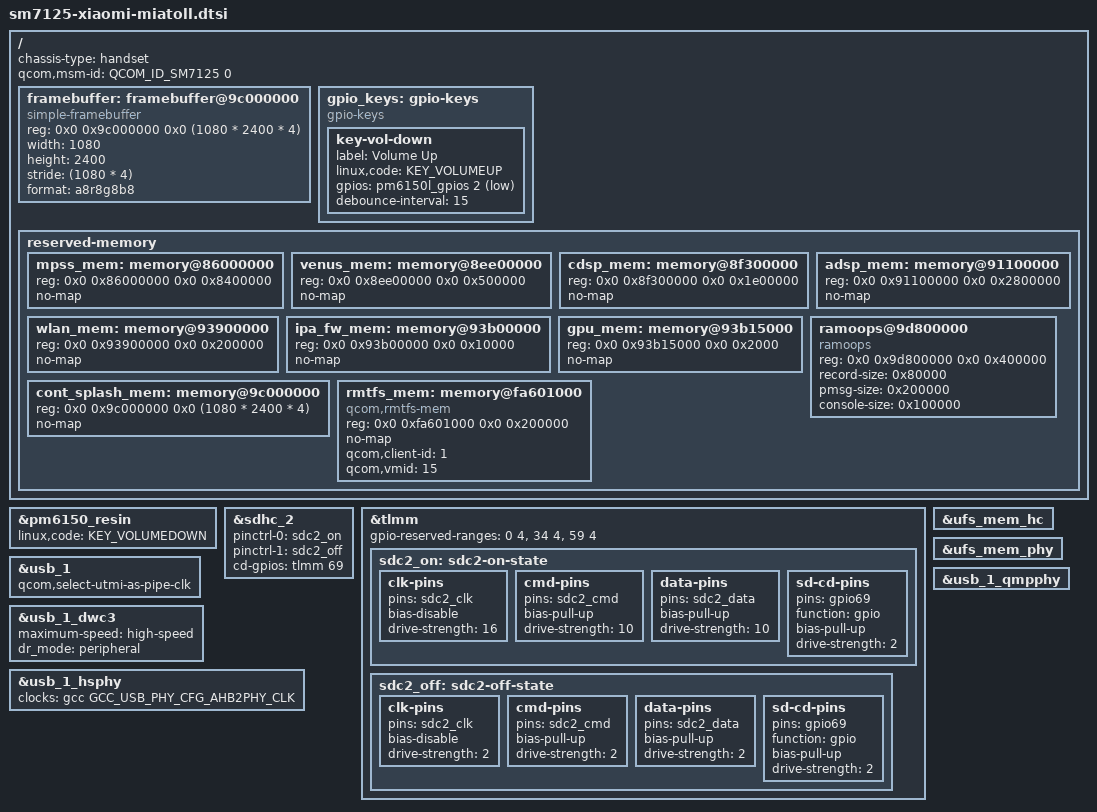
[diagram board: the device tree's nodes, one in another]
// SPDX-License-Identifier: GPL-2.0
/*
 * Copyright (c) 2023, David Wronek <davidwronek@gmail.com>
 */

/dts-v1/;

#include <dt-bindings/arm/qcom,ids.h>
#include <dt-bindings/gpio/gpio.h>
#include <dt-bindings/input/linux-event-codes.h>

#include "sm7125.dtsi"
#include "pm6150.dtsi"
#include "pm6150l.dtsi"

/delete-node/ &ipa_fw_mem;
/delete-node/ &rmtfs_mem;

/ {
	chassis-type = "handset";

	qcom,msm-id = <QCOM_ID_SM7125 0>;

	framebuffer: framebuffer@9c000000 {
		compatible = "simple-framebuffer";
		reg = <0x0 0x9c000000 0x0 (1080 * 2400 * 4)>;
		width = <1080>;
		height = <2400>;
		stride = <(1080 * 4)>;
		format = "a8r8g8b8";
	};

	
	gpio_keys: gpio-keys {
		compatible = "gpio-keys";

		key-vol-down {
			label = "Volume Up";
			linux,code = <KEY_VOLUMEUP>;
			gpios = <&pm6150l_gpios 2 GPIO_ACTIVE_LOW>;
			debounce-interval = <15>;
		};
	};

	reserved-memory {
				mpss_mem: memory@86000000 {
			reg = <0x0 0x86000000 0x0 0x8400000>;
			no-map;
		};

		venus_mem: memory@8ee00000 {
			reg = <0x0 0x8ee00000 0x0 0x500000>;
			no-map;
		};

		cdsp_mem: memory@8f300000 {
			reg = <0x0 0x8f300000 0x0 0x1e00000>;
			no-map;
		};

		adsp_mem: memory@91100000 {
			reg = <0x0 0x91100000 0x0 0x2800000>;
			no-map;
		};

		wlan_mem: memory@93900000 {
			reg = <0x0 0x93900000 0x0 0x200000>;
			no-map;
		};

		ipa_fw_mem: memory@93b00000 {
			reg = <0x0 0x93b00000 0x0 0x10000>;
			no-map;
		};

		gpu_mem: memory@93b15000 {
			reg = <0x0 0x93b15000 0x0 0x2000>;
			no-map;
		};

		cont_splash_mem: memory@9c000000 {
			reg = <0x0 0x9c000000 0x0 (1080 * 2400 * 4)>;
			no-map;
		};

		ramoops@9d800000 {
			compatible = "ramoops";
			reg = <0x0 0x9d800000 0x0 0x400000>;

			record-size = <0x80000>;
			pmsg-size = <0x200000>;
			console-size = <0x100000>;
		};

		rmtfs_mem: memory@fa601000 {
			compatible = "qcom,rmtfs-mem";
			reg = <0x0 0xfa601000 0x0 0x200000>;
			no-map;

			qcom,client-id = <1>;
			qcom,vmid = <15>;
		};
	};
};

&pm6150_resin {
    linux,code = <KEY_VOLUMEDOWN>;
    status = "okay";
};

&sdhc_2 {
	status = "okay";

	pinctrl-names = "default","sleep";
	pinctrl-0 = <&sdc2_on>;
	pinctrl-1 = <&sdc2_off>;

	cd-gpios = <&tlmm 69 GPIO_ACTIVE_HIGH>;
};

&tlmm {
	gpio-reserved-ranges = <0 4>, <34 4>, <59 4>;

	sdc2_on: sdc2-on-state {
		clk-pins {
			pins = "sdc2_clk";
			bias-disable;
			drive-strength = <16>;
		};

		cmd-pins {
			pins = "sdc2_cmd";
			bias-pull-up;
			drive-strength = <10>;
		};

		data-pins {
			pins = "sdc2_data";
			bias-pull-up;
			drive-strength = <10>;
		};

		sd-cd-pins {
			pins = "gpio69";
			function = "gpio";
			bias-pull-up;
			drive-strength = <2>;
		};
	};

	sdc2_off: sdc2-off-state {
		clk-pins {
			pins = "sdc2_clk";
			bias-disable;
			drive-strength = <2>;
		};

		cmd-pins {
			pins = "sdc2_cmd";
			bias-pull-up;
			drive-strength = <2>;
		};

		data-pins {
			pins = "sdc2_data";
			bias-pull-up;
			drive-strength = <2>;
		};

		sd-cd-pins {
			pins = "gpio69";
			function = "gpio";
			bias-pull-up;
			drive-strength = <2>;
		};
	};
};

&ufs_mem_hc {
	status = "okay";
};

&ufs_mem_phy {
	status = "okay";
};

&usb_1 {
	qcom,select-utmi-as-pipe-clk;
	status = "okay";
};

&usb_1_dwc3 {
	maximum-speed = "high-speed";
	dr_mode = "peripheral";
	status = "okay";
};

&usb_1_hsphy {
	/* Remove ref clk because rmphcc isn't available */
	clocks = <&gcc GCC_USB_PHY_CFG_AHB2PHY_CLK>;
	clock-names = "cfg_ahb";

	status = "okay";
};

&usb_1_qmpphy {
	status = "okay";
};
